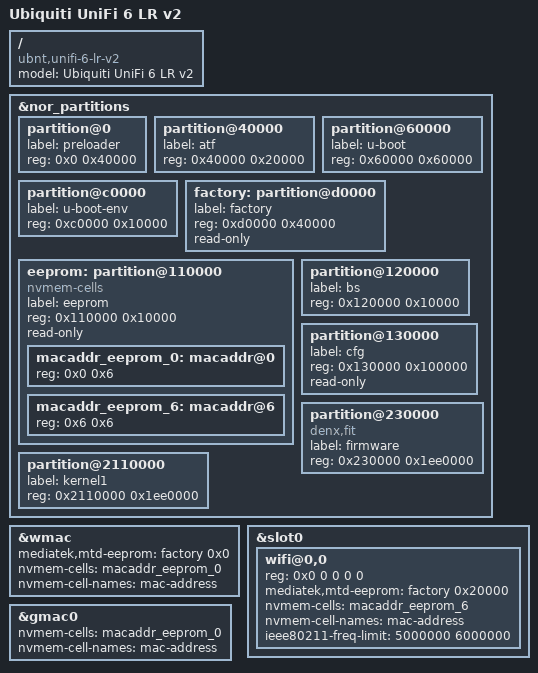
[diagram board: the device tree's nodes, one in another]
// SPDX-License-Identifier: GPL-2.0-or-later OR MIT

#include "mt7622-ubnt-unifi-6-lr-v2.dtsi"

/ {
	model = "Ubiquiti UniFi 6 LR v2";
	compatible = "ubnt,unifi-6-lr-v2", "mediatek,mt7622";
};

&nor_partitions {
	partition@0 {
		label = "preloader";
		reg = <0x0 0x40000>;
	};

	partition@40000 {
		label = "atf";
		reg = <0x40000 0x20000>;
	};

	partition@60000 {
		label = "u-boot";
		reg = <0x60000 0x60000>;
	};

	partition@c0000 {
		label = "u-boot-env";
		reg = <0xc0000 0x10000>;
	};

	factory: partition@d0000 {
		label = "factory";
		reg = <0xd0000 0x40000>;
		read-only;
	};

	eeprom: partition@110000 {
		label = "eeprom";
		reg = <0x110000 0x10000>;
		read-only;
	};

	partition@120000 {
		label = "bs";
		reg = <0x120000 0x10000>;
	};

	partition@130000 {
		label = "cfg";
		reg = <0x130000 0x100000>;
		read-only;
	};

	partition@230000 {
		compatible = "denx,fit";
		label = "firmware";
		reg = <0x230000 0x1ee0000>;
	};

	partition@2110000 {
		label = "kernel1";
		reg = <0x2110000 0x1ee0000>;
	};
};

&wmac {
	mediatek,mtd-eeprom = <&factory 0x0>;
	nvmem-cells = <&macaddr_eeprom_0>;
	nvmem-cell-names = "mac-address";
	status = "okay";
};

&slot0 {
	wifi@0,0 {
		reg = <0x0 0 0 0 0>;
		mediatek,mtd-eeprom = <&factory 0x20000>;
		nvmem-cells = <&macaddr_eeprom_6>;
		nvmem-cell-names = "mac-address";
		ieee80211-freq-limit = <5000000 6000000>;
	};
};

&gmac0 {
	nvmem-cells = <&macaddr_eeprom_0>;
	nvmem-cell-names = "mac-address";
};

&eeprom {
	compatible = "nvmem-cells";
	#address-cells = <1>;
	#size-cells = <1>;

	macaddr_eeprom_0: macaddr@0 {
		reg = <0x0 0x6>;
	};

	macaddr_eeprom_6: macaddr@6 {
		reg = <0x6 0x6>;
	};
};
